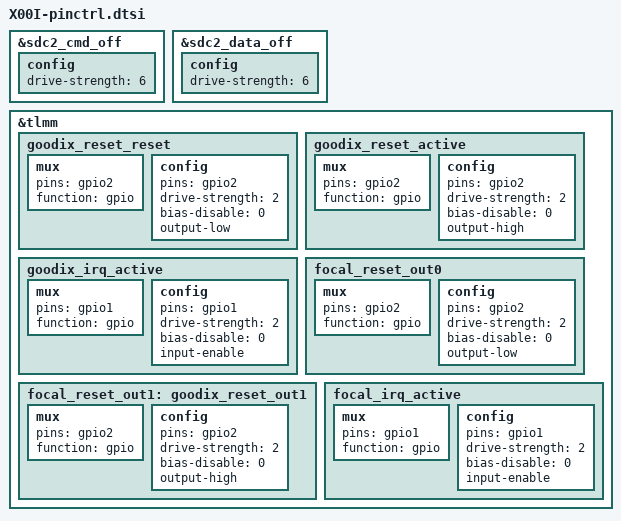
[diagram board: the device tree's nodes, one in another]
/*
 * Copyright (c) 2015-2018, The Linux Foundation. All rights reserved.
 *
 * This program is free software; you can redistribute it and/or modify
 * it under the terms of the GNU General Public License version 2 and
 * only version 2 as published by the Free Software Foundation.
 *
 * This program is distributed in the hope that it will be useful,
 * but WITHOUT ANY WARRANTY; without even the implied warranty of
 * MERCHANTABILITY or FITNESS FOR A PARTICULAR PURPOSE.  See the
 * GNU General Public License for more details.
 */

&sdc2_cmd_off {
	config {
		drive-strength = <6>;
	};
};

&sdc2_data_off {
	config {
		drive-strength = <6>;
	};
};

&tlmm {
	goodix_reset_reset: goodix_reset_reset {
		mux {
			pins = "gpio2";
			function = "gpio";
		};

		config {
			pins = "gpio2";
			drive-strength = <2>;
			bias-disable = <0>;
			output-low;
		};
	};

	goodix_reset_active: goodix_reset_active {
		mux {
			pins = "gpio2";
			function = "gpio";
		};

		config {
			pins = "gpio2";
			drive-strength = <2>;
			bias-disable = <0>;
			output-high;
		};
	};

	goodix_irq_active: goodix_irq_active {
		mux {
			pins = "gpio1";
			function = "gpio";
		};

		config {
			pins = "gpio1";
			drive-strength = <2>;
			bias-disable = <0>;
			input-enable;
		};
	};

	focal_reset_out0: focal_reset_out0 {
		mux {
			pins = "gpio2";
			function = "gpio";
		};

		config {
			pins = "gpio2";
			drive-strength = <2>;
			bias-disable = <0>;
			output-low;
		};
	};

	focal_reset_out1: goodix_reset_out1 {
		mux {
			pins = "gpio2";
			function = "gpio";
		};

		config {
			pins = "gpio2";
			drive-strength = <2>;
			bias-disable = <0>;
			output-high;
		};
	};

	focal_irq_active: focal_irq_active {
		mux {
			pins = "gpio1";
			function = "gpio";
		};

		config {
			pins = "gpio1";
			drive-strength = <2>;
			bias-disable = <0>;
			input-enable;
		};
	};
};
